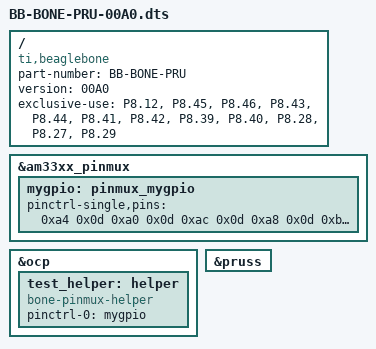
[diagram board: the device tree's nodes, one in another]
/*
* pru dts file BB-BONE-PRU-00A0.dts
*/
/dts-v1/;
/plugin/;

/ {
  compatible = "ti,beaglebone", "ti,beaglebone-black";

  /* identification */
  part-number = "BB-BONE-PRU";
  version = "00A0";

  exclusive-use =
    
"P8.12","P8.45","P8.46","P8.43","P8.44","P8.41","P8.42","P8.39","P8.40","P8.28","P8.27","P8.29";

  fragment@0 {
    target = <&am33xx_pinmux>;
    __overlay__ {
      mygpio: pinmux_mygpio{
        pinctrl-single,pins = <

  /*5 pwm and 5 enable bits beta*/
	0xa4 0x0d	/* p8_46 to PRU output */
	0xa0 0x0d	/* p8_45 to PRU output */
	0xac 0x0d	/* p8_44 to PRU output */
	0xa8 0x0d	/* p8_43 to PRU output */
	0xb4 0x0d	/* p8_42 to PRU output */
	0xb0 0x0d	/* p8_41 to PRU output */
	0xbc 0x0d	/* p8_40 to PRU output */
	0xb8 0x0d	/* p8_39 to PRU output */
	0xe4 0x0d	/* p8_29 to PRU output */
	0xe8 0x0d	/* p8_28 to PRU output */

          /*0x30 0x06 0xa0 0x0d 0xa4 0x0d 0xa8 0x0d 0xac 0x0d 0xb0 0x0d 
0xb4 0x2e 0xb8 0x2e 0xbc 0x2e 0xe8 0x2e 0xe0 0x0d 0xe4 0x2e*/
          >;
      };
    };
  };

  fragment@1 {
    target = <&ocp>;
    __overlay__ {
      test_helper: helper {
        compatible = "bone-pinmux-helper";
        pinctrl-names = "default";
        pinctrl-0 = <&mygpio>;
        status = "okay";
      };
    };
  };

  fragment@2{
  target = <&pruss>;
    __overlay__ {
      status = "okay";
    };
  };
};
